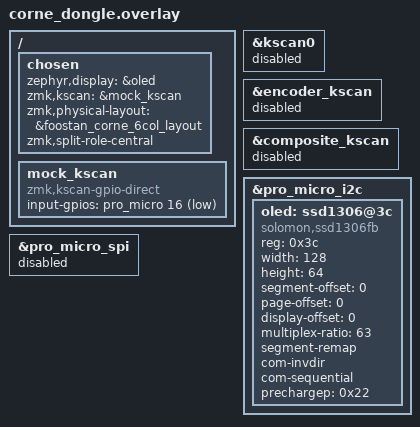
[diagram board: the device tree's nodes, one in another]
#include "../../../corne.dtsi"

/ {
    chosen {
        zephyr,display = &oled;
        zmk,kscan = &mock_kscan;
        zmk,physical-layout = &foostan_corne_6col_layout;
        zmk,split-role-central;  // Dongle is central
    };
    
    mock_kscan: mock_kscan {
        compatible = "zmk,kscan-gpio-direct";
        input-gpios = <&pro_micro 16 (GPIO_ACTIVE_LOW | GPIO_PULL_UP)>;
    };
};

// Disable inherited kscans from corne.dtsi
&kscan0 {
    status = "disabled";
};

&encoder_kscan {
    status = "disabled";
};

&composite_kscan {
    status = "disabled";
};

// Enable I2C for OLED on dongle only
&pro_micro_i2c {
    status = "okay";
    
    oled: ssd1306@3c {
        compatible = "solomon,ssd1306fb";
        reg = <0x3c>;
        width = <128>;
        height = <64>;
        segment-offset = <0>;
        page-offset = <0>;
        display-offset = <0>;
        multiplex-ratio = <63>;
        segment-remap;
        com-invdir;
        com-sequential;  // Add this line
        prechargep = <0x22>;
    };
};

&pro_micro_spi {
    status = "disabled";
};
